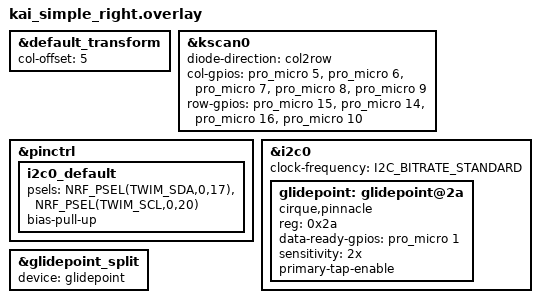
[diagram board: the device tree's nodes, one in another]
/*
 * Copyright (c) 2020 The ZMK Contributors
 *
 * SPDX-License-Identifier: MIT
 */

#include "kai_simple.dtsi"

#include <input/processors.dtsi>
#include <dt-bindings/zmk/input_transform.h>
#include "glidepoint_shared.dtsi"

&default_transform {
    col-offset = <5>;
};

&kscan0 {
    diode-direction = "col2row";
    col-gpios
        = <&pro_micro 5 (GPIO_ACTIVE_HIGH)> // COL0
        , <&pro_micro 6 (GPIO_ACTIVE_HIGH)> // COL1
        , <&pro_micro 7 (GPIO_ACTIVE_HIGH)> // COL2
        , <&pro_micro 8 (GPIO_ACTIVE_HIGH)> // COL3
        , <&pro_micro 9 (GPIO_ACTIVE_HIGH)> // COL4
    ;
    row-gpios
        = <&pro_micro 15 (GPIO_ACTIVE_HIGH | GPIO_PULL_DOWN)> // ROW0
        , <&pro_micro 14 (GPIO_ACTIVE_HIGH | GPIO_PULL_DOWN)> // ROW1
        , <&pro_micro 16 (GPIO_ACTIVE_HIGH | GPIO_PULL_DOWN)> // ROW2
        , <&pro_micro 10 (GPIO_ACTIVE_HIGH | GPIO_PULL_DOWN)> // ROW3
    ;
};
&pinctrl {
    i2c0_default: i2c0_default{
        psels = <NRF_PSEL(TWIM_SDA,0,17)>,
                <NRF_PSEL(TWIM_SCL,0,20)>;
        bias-pull-up;
    };
};

&i2c0 {
    status = "okay";
    clock-frequency = <I2C_BITRATE_STANDARD>;

    glidepoint: glidepoint@2a {
        compatible = "cirque,pinnacle";
        reg = <0x2a>;
        status = "okay";
        data-ready-gpios = <&pro_micro 1 (GPIO_ACTIVE_HIGH)>; // 006 - CS
        sensitivity = "2x";
        primary-tap-enable;
    };
};

&glidepoint_split {
    device = <&glidepoint>;
};
